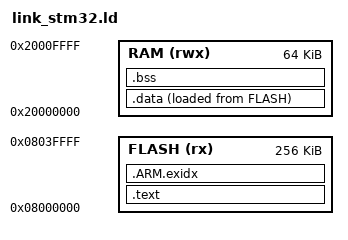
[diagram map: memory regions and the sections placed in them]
/* Generic STM32 Cortex-M4: 256 KB flash at 0x08000000, 64 KB SRAM. */
MEMORY {
  FLASH (rx) : ORIGIN = 0x08000000, LENGTH = 256K
  RAM (rwx)  : ORIGIN = 0x20000000, LENGTH = 64K
}
ENTRY(reset_handler)
_estack = ORIGIN(RAM) + LENGTH(RAM);
SECTIONS {
  .text : { KEEP(*(.vectors)) *(.text*) *(.rodata*) . = ALIGN(4); } > FLASH
  .ARM.exidx : { *(.ARM.exidx*) } > FLASH
  _sidata = LOADADDR(.data);
  .data : { _sdata = .; *(.data*) . = ALIGN(4); _edata = .; } > RAM AT > FLASH
  .bss (NOLOAD) : { _sbss = .; *(.bss*) *(COMMON) . = ALIGN(4); _ebss = .; } > RAM
}
